VERSION ""

NS_ :

BS_:

BU_: Vehicle_Control_Unit

BO_ 773 VCU_TPS_CurrentValue: 4 Vehicle_Control_Unit
 SG_ TPS_SecondaryCurrentVal : 16|16@1+ (1,0) [0|65535] "" Vector__XXX
 SG_ TPS_PrimaryCurrentVal : 0|16@1+ (1,0) [0|65535] "" Vector__XXX

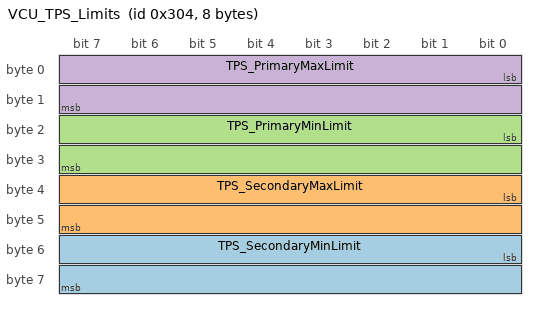
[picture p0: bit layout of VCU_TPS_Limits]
BO_ 772 VCU_TPS_Limits: 8 Vehicle_Control_Unit
 SG_ TPS_SecondaryMinLimit : 48|16@1+ (1,0) [0|65535] "" Vector__XXX
 SG_ TPS_SecondaryMaxLimit : 32|16@1+ (1,0) [0|65535] "" Vector__XXX
 SG_ TPS_PrimaryMinLimit : 16|16@1+ (1,0) [0|65535] "" Vector__XXX
 SG_ TPS_PrimaryMaxLimit : 0|16@1+ (1,0) [0|65535] "" Vector__XXX

BA_DEF_  "BusType" STRING ;
BA_DEF_DEF_  "BusType" "CAN";
